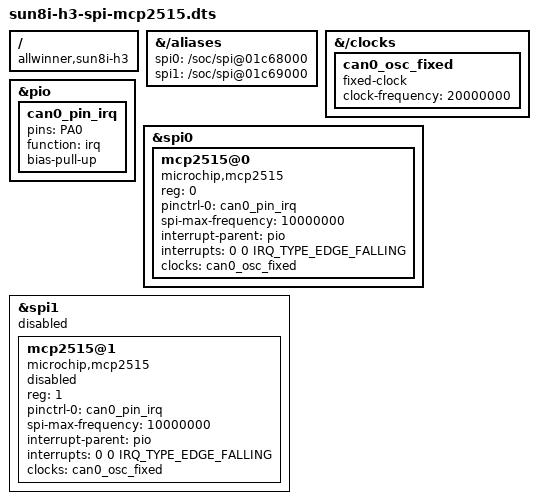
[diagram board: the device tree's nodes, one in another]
/dts-v1/ /plugin/;

#include <dt-bindings/interrupt-controller/irq.h>

/ {
	compatible = "allwinner,sun8i-h3";

	fragment@0 {
		target-path = "/aliases";
		__overlay__ {
			spi0 = "/soc/spi@01c68000";
			spi1 = "/soc/spi@01c69000";
		};
	};

	fragment@1 {
		target-path = "/clocks";
		__overlay__ {
			#address-cells = <1>;
			#size-cells = <1>;
			can0_osc_fixed: can0_osc_fixed {
				compatible = "fixed-clock";
				#clock-cells = <0>;
				clock-frequency  = <20000000>;
			};
		};
	};

	fragment@2 {
		target = <&pio>;
		__overlay__ {
			can0_pin_irq: can0_pin_irq {
				pins = "PA0"; 				/* PA0 Connected to Cactus Pot CAN-INT */
				function = "irq";
				bias-pull-up;
			};
		};
	};

	fragment@3 {
		target = <&spi0>;
		__overlay__ {
			#address-cells = <1>;
			#size-cells = <0>;
			status = "okay";

			mcp2515@0 {
				reg = <0>;
				compatible = "microchip,mcp2515";
				pinctrl-names = "default";
				pinctrl-0 = <&can0_pin_irq>;
				spi-max-frequency = <10000000>;             /* Temporary required because long wires connected! */
				interrupt-parent = <&pio>;
				interrupts = <0 0 IRQ_TYPE_EDGE_FALLING>; /* PA0 Connected to Cactus Pot CAN-INT */
				clocks = <&can0_osc_fixed>;
				status = "okay";
			};
		};
	};

	fragment@4 {
		target = <&spi1>;
		__overlay__ {
			#address-cells = <1>;
			#size-cells = <0>;
			status = "disabled";

			mcp2515@1 {
				reg = <1>;
				compatible = "microchip,mcp2515";
				pinctrl-names = "default";
				pinctrl-0 = <&can0_pin_irq>;
				spi-max-frequency = <10000000>;
				interrupt-parent = <&pio>;
				interrupts = <0 0 IRQ_TYPE_EDGE_FALLING>; /* PA0 Connected to Cactus Pot CAN-INT */
				clocks = <&can0_osc_fixed>;
				status = "disabled";
			};
		};
	};
};
